# QEMU_RISCV_VIRT register map
Vendor: qemu.org; Series: RISC-V; File version: 0.1
QEMU RISC-V Virt Machine Platform
CPU: riscv r0p0, little endian, no MPU, no FPU, 0 interrupt priority bits
Registers are 32-bit, read-write, reset 0x0 unless marked. A register's access mark holds for its fields unless they carry their own. Offsets are from the block's base; lines under a group give offsets from that group; [hi:lo] are bit positions; {n}, {i} and the like mark numbered series; 'fields as' and 'values as' point back to an identical list; <NAME> marks a mode.

## Memory map
0x02000000 CLINT size 0x10000 — Core Local Interruptor (SiFive CLINT compatible)
0x0C000000 PLIC size 0x201000 — Platform-Level Interrupt Controller (SiFive PLIC compatible)
0x10000000 UART0 size 0x1000 — NS16550A compatible UART
0x10001000 I2C0 size 0x1000 — ODP socket-backed I2C controller
0x10002000 I2C_TARGET size 0x1000 — ODP socket-backed I2C target
0x10003000 GPIO size 0x1000 — ODP socket-backed bidirectional GPIO controller (32 pins, one bit per pin)
0x10004000 ESPI_TARGET size 0x1000 — ODP socket-backed eSPI target. Registers require aligned 32-bit accesses. Host addresses are independent of the EC mailbox memory windows.
0x10005000 ESPI_MAILBOX0 size 0x1000 — Fixed 4-KiB EC view of eSPI mailbox zero RAM. The host decode base does not relocate this window. Supports aligned 8-, 16- and 32-bit accesses; data accesses do not ring the doorbell.
0x10006000 ESPI_MAILBOX1 size 0x1000 — Fixed EC view of eSPI mailbox one RAM, independent of its configurable host address

## Interrupts
1 UART0 — UART0 interrupt (PLIC source 1)
2 I2C0 — I2C0 controller interrupt (PLIC source 2)
3 I2C_TARGET — I2C target interrupt (PLIC source 3)
4 GPIO — GPIO shared interrupt (PLIC source 4)
5 ESPI_TARGET — eSPI target shared level interrupt (PLIC source 5)

## CLINT — Core Local Interruptor (SiFive CLINT compatible)
Base 0x02000000
0x00 MSIP — Machine Software Interrupt Pending for hart 0
  [0] MSIP — Machine software interrupt pending
0x4000 MTIMECMP_LO — Machine timer compare low word for hart 0
0x4004 MTIMECMP_HI — Machine timer compare high word for hart 0
0xBFF8 MTIME_LO — Machine timer low word
0xBFFC MTIME_HI — Machine timer high word

## PLIC — Platform-Level Interrupt Controller (SiFive PLIC compatible)
Base 0x0C000000
{0x0+4i} PRIORITY[{i}] (i=0..31) — Priority for interrupt source {i} (source 0 is reserved)
  [2:0] PRIORITY — Priority level (0=disabled, 1=lowest, 7=highest)
{0x1000+4i} PENDING{i} (i=0..0) ro — Interrupt pending bits
{0x2000+4i} M_ENABLE{i} (i=0..0) — M-mode interrupt enable bits (context 0)
0x200000 M_THRESHOLD — M-mode priority threshold (context 0)
  [2:0] THRESHOLD — Priority threshold (interrupts with priority <= threshold are masked)
0x200004 M_CLAIM — M-mode interrupt claim/complete (context 0). Read to claim, write to complete.

## UART0 — NS16550A compatible UART
Base 0x10000000
0x00 DATA group — UART registers when DLAB=0
  0x00 RBR 8-bit ro — Receiver Buffer Register (DLAB=0)
  0x00 THR 8-bit wo — Transmitter Holding Register (DLAB=0)
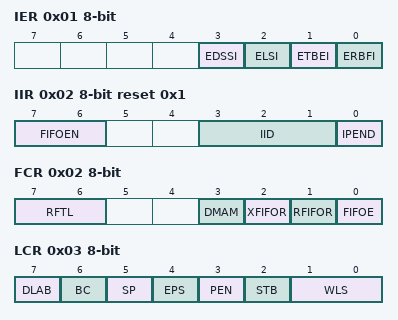
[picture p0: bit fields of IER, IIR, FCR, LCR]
  0x01 IER 8-bit — Interrupt Enable Register (DLAB=0)
    [3] EDSSI — Enable Modem Status Interrupt
    [2] ELSI — Enable Receiver Line Status Interrupt
    [1] ETBEI — Enable Transmitter Holding Register Empty Interrupt
    [0] ERBFI — Enable Received Data Available Interrupt
  0x02 IIR 8-bit ro reset 0x1 — Interrupt Identification Register
    [7:6] FIFOEN — FIFOs enabled
    [3:1] IID — Interrupt ID
    [0] IPEND — Interrupt NOT pending (0 = interrupt pending)
  0x02 FCR 8-bit wo — FIFO Control Register
    [7:6] RFTL — Receiver FIFO trigger level
    [3] DMAM — DMA mode select
    [2] XFIFOR — Transmitter FIFO reset (self-clearing)
    [1] RFIFOR — Receiver FIFO reset (self-clearing)
    [0] FIFOE — FIFO enable
  0x03 LCR 8-bit — Line Control Register
    [7] DLAB — Divisor latch access bit
    [6] BC — Break control
    [5] SP — Stick parity
    [4] EPS — Even parity select
    [3] PEN — Parity enable
    [2] STB — Number of stop bits
    [1:0] WLS — Word length select
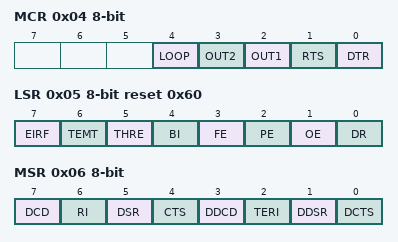
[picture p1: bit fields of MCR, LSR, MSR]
  0x04 MCR 8-bit — Modem Control Register
    [4] LOOP — Loopback mode
    [3] OUT2 — Output 2
    [2] OUT1 — Output 1
    [1] RTS — Request to send
    [0] DTR — Data terminal ready
  0x05 LSR 8-bit ro reset 0x60 — Line Status Register
    [7] EIRF — Error in receiver FIFO
    [6] TEMT — Transmitter empty
    [5] THRE — Transmitter holding register empty
    [4] BI — Break interrupt
    [3] FE — Framing error
    [2] PE — Parity error
    [1] OE — Overrun error
    [0] DR — Data ready
  0x06 MSR 8-bit ro — Modem Status Register
    [7] DCD — Data carrier detect
    [6] RI — Ring indicator
    [5] DSR — Data set ready
    [4] CTS — Clear to send
    [3] DDCD — Delta data carrier detect
    [2] TERI — Trailing edge ring indicator
    [1] DDSR — Delta data set ready
    [0] DCTS — Delta clear to send
  0x07 SCR 8-bit — Scratch Register
0x00 DLAB group (alternate view of DATA) — UART registers when DLAB=1
  0x00 DLL 8-bit — Divisor Latch LSB (DLAB=1)
  0x01 DLM 8-bit — Divisor Latch MSB (DLAB=1)
  0x02 IIR 8-bit ro reset 0x1 — Interrupt Identification Register
    fields as DATA.IIR
  0x02 FCR 8-bit wo — FIFO Control Register
    fields as DATA.FCR
  0x03 LCR 8-bit — Line Control Register
    fields as DATA.LCR
  0x04 MCR 8-bit — Modem Control Register
    fields as DATA.MCR
  0x05 LSR 8-bit ro reset 0x60 — Line Status Register
    fields as DATA.LSR
  0x06 MSR 8-bit ro — Modem Status Register
    fields as DATA.MSR
  0x07 SCR 8-bit — Scratch Register
